# STM32U5A9 register map
File version: 0.2
CPU: CM33 r0p1, little endian, MPU, FPU, 4 interrupt priority bits
Registers are 32-bit, read-write, reset 0x0 unless marked. A register's access mark holds for its fields unless they carry their own. Offsets are from the block's base; [hi:lo] are bit positions; {n}, {i} and the like mark numbered series; 'fields as' and 'values as' point back to an identical list.

## PSSI
Base 0x4202C400
Same registers: SEC_PSSI 0x5202C400
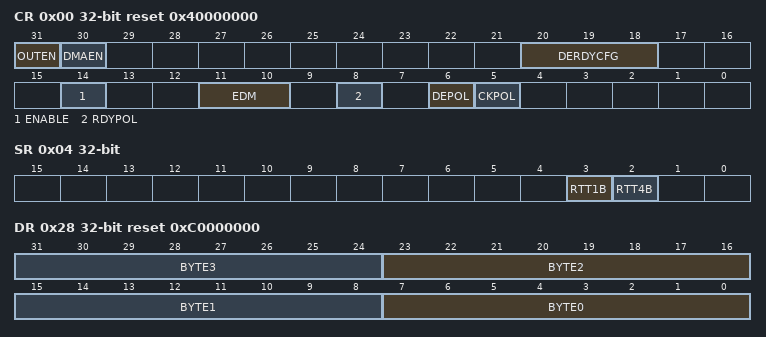
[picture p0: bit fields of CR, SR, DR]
0x00 CR reset 0x40000000 — PSSI control register
  [31] OUTEN — Data direction selection bit
  [30] DMAEN — DMA enable bit
  [20:18] DERDYCFG — Data enable and ready configuration When the PSSI_RDY function is mapped to the PSSI_DE pin (settings 101 or 111), it is still the RDYPOL bit which determines its polarity. Similarly, when the PSSI_DE function is mapped to the PSSI_RDY pin (settings 110 or 111), it is still the DEPOL bit which determines its polarity.
  [14] ENABLE — PSSI enable The contents of the FIFO are flushed when ENABLE is cleared to 0. Note: When ENABLE=1, the content of PSSI_CR must not be changed, except for the ENABLE bit itself. All configuration bits can change as soon as ENABLE changes from 0 to 1. The DMA controller and all PSSI configuration registers must be programmed correctly before setting the ENABLE bit to 1. The ENABLE bit and the DCMI ENABLE bit (bit 15 of DCMI_CR) must not be set to 1 at the same time.
  [11:10] EDM — Extended data mode
  [8] RDYPOL — Ready (PSSI_RDY) polarity This bit indicates the level on the PSSI_RDY pin when the data are not valid on the parallel interface.
  [6] DEPOL — Data enable (PSSI_DE) polarity This bit indicates the level on the PSSI_DE pin when the data are not valid on the parallel interface.
  [5] CKPOL — Parallel data clock polarity This bit configures the capture edge of the parallel clock or the edge used for driving outputs, depending on OUTEN.
0x04 SR ro — PSSI status register
  [3] RTT1B, [2] RTT4B
0x08 RIS ro — PSSI raw interrupt status register
  [1] OVR_RIS
0x0C IER — PSSI interrupt enable register
  [1] OVR_IE
0x10 MIS ro — PSSI masked interrupt status register
  [1] OVR_MIS
0x14 ICR wo — PSSI interrupt clear register
  [1] OVR_ISC
0x28 DR reset 0xC0000000 — PSSI data register
  [8n+7:8n] BYTE{n} (n=0..3) — Data byte {n}

## RAMCFG
Base 0x40026000
Same registers: SEC_RAMCFG 0x50026000
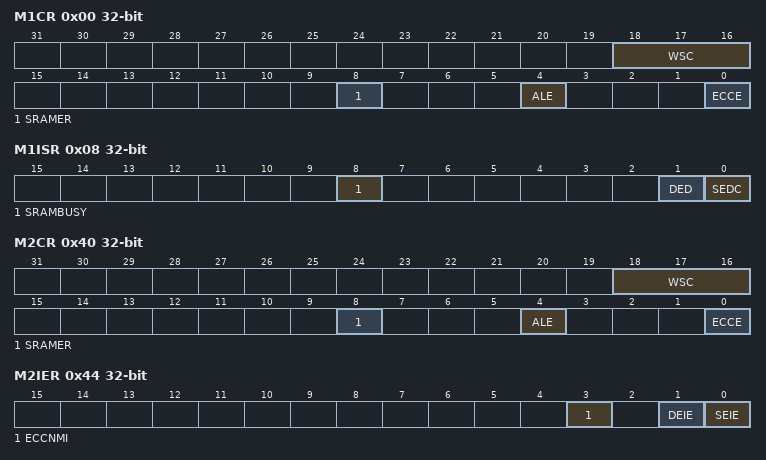
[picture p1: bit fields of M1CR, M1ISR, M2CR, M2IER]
0x00 M1CR — RAMCFG SRAM x control register
  [18:16] WSC, [8] SRAMER, [4] ALE, [0] ECCE
0x08 M1ISR ro — RAMCFG RAMx interrupt status register
  [8] SRAMBUSY, [1] DED, [0] SEDC
0x28 RAM1ERKEYR wo — RAMCFG SRAM x erase key register
  [7:0] ERASEKEY
0x40 M2CR — RAMCFG SRAM x control register
  [18:16] WSC, [8] SRAMER, [4] ALE, [0] ECCE
0x44 M2IER — RAMCFG SRAM x interrupt enable register
  [3] ECCNMI, [1] DEIE, [0] SEIE
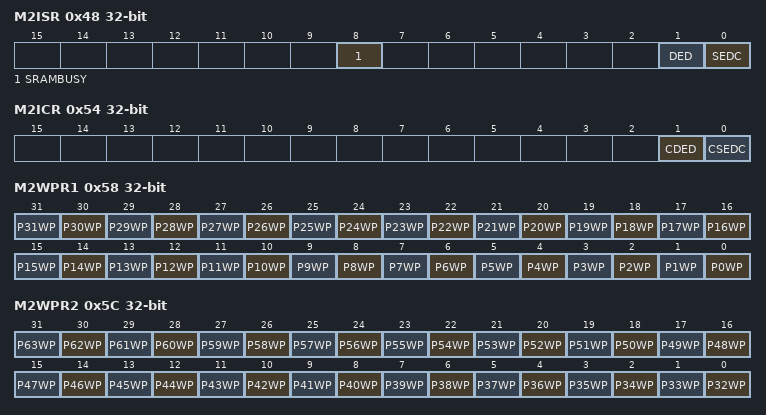
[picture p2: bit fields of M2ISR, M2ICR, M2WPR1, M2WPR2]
0x48 M2ISR ro — RAMCFG RAMx interrupt status register
  [8] SRAMBUSY, [1] DED, [0] SEDC
0x4C M2SEAR ro — RAMCFG RAM x ECC single error address register
  [31:0] ESEA
0x50 M2DEAR ro — RAMCFG RAM x ECC double error address register
  [31:0] EDEA
0x54 M2ICR — RAMCFG RAM x interrupt clear register x
  [1] CDED, [0] CSEDC
0x58 M2WPR1 — RAMCFG SRAM2 write protection register 1
  [n] P{n}WP (n=0..31)
0x5C M2WPR2 — RAMCFG SRAM2 write protection register 2
  [n-32] P{n}WP (n=32..63)
0x64 M2ECCKEYR wo — RAMCFG SRAM x ECC key register
  [7:0] ECCKEY
0x68 M2ERKEYR wo — RAMCFG SRAM x erase key register
  [7:0] ERASEKEY
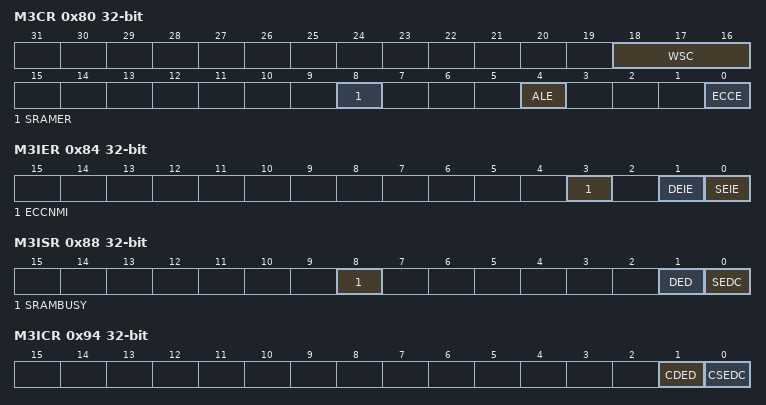
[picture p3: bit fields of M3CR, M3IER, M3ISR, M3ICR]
0x80 M3CR — RAMCFG SRAM x control register
  [18:16] WSC, [8] SRAMER, [4] ALE, [0] ECCE
0x84 M3IER — RAMCFG SRAM x interrupt enable register
  [3] ECCNMI, [1] DEIE, [0] SEIE
0x88 M3ISR ro — RAMCFG RAMx interrupt status register
  [8] SRAMBUSY, [1] DED, [0] SEDC
0x8C M3SEAR ro — RAMCFG RAM x ECC single error address register
  [31:0] ESEA
0x90 M3DEAR ro — RAMCFG RAM x ECC double error address register
  [31:0] EDEA
0x94 M3ICR — RAMCFG RAM x interrupt clear register x
  [1] CDED, [0] CSEDC
0xA4 M3ECCKEYR wo — RAMCFG SRAM x ECC key register
  [7:0] ECCKEY
0xA8 M3ERKEYR wo — RAMCFG SRAM x erase key register
  [7:0] ERASEKEY
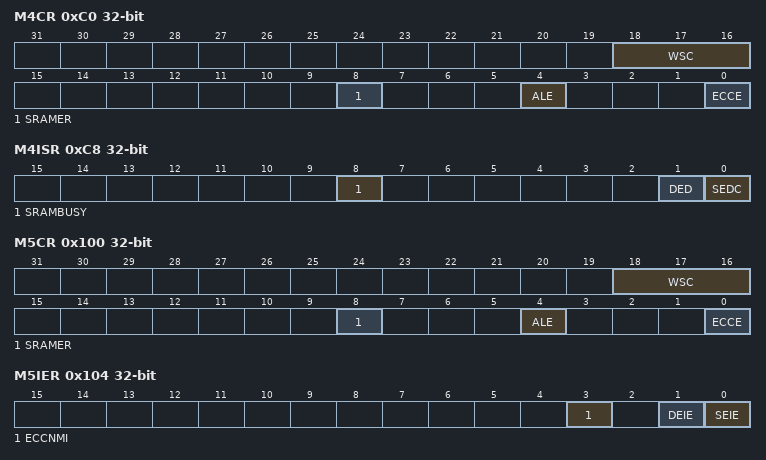
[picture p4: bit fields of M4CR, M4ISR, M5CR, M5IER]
0xC0 M4CR — RAMCFG SRAM x control register
  [18:16] WSC, [8] SRAMER, [4] ALE, [0] ECCE
0xC8 M4ISR ro — RAMCFG RAMx interrupt status register
  [8] SRAMBUSY, [1] DED, [0] SEDC
0xE8 M4ERKEYR wo — RAMCFG SRAM x erase key register
  [7:0] ERASEKEY
0x100 M5CR — RAMCFG SRAM x control register
  [18:16] WSC, [8] SRAMER, [4] ALE, [0] ECCE
0x104 M5IER — RAMCFG SRAM x interrupt enable register
  [3] ECCNMI, [1] DEIE, [0] SEIE
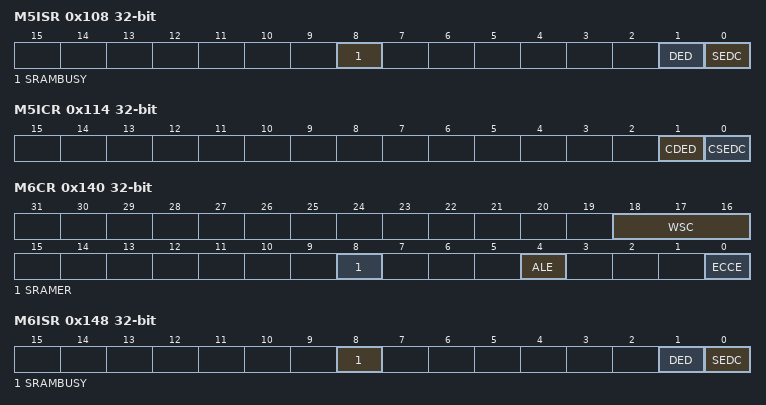
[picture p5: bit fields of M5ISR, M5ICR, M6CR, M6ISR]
0x108 M5ISR ro — RAMCFG RAMx interrupt status register
  [8] SRAMBUSY, [1] DED, [0] SEDC
0x10C M5SEAR ro — RAMCFG RAM x ECC single error address register
  [31:0] ESEA
0x110 M5DEAR ro — RAMCFG RAM x ECC double error address register
  [31:0] EDEA
0x114 M5ICR — RAMCFG RAM x interrupt clear register x
  [1] CDED, [0] CSEDC
0x124 M5ECCKEYR — RAMCFG RAM x interrupt clear register x
  [7:0] ECCKEY
0x128 M5ERKEYR
  [7:0] ERASEKEY wo — Erase write protection key The following steps are required to unlock the write protection of the SRAMER bit in the RAMCFG_MxCR register. 1) Write 0xCA into ERASEKEY[7:0]. 2) Write 0x53 into ERASEKEY[7:0]. Note: Writing a wrong key reactivates the write protection.
0x140 M6CR — memory x control register
  [18:16] WSC, [8] SRAMER, [4] ALE, [0] ECCE
0x148 M6ISR ro
  [8] SRAMBUSY — SRAM busy with erase operation Note: Depending on the SRAM, the erase operation can be performed due to software request, system reset if the option bit is enabled, tamper detection or readout protection regression. Refer to .
  [1] DED — ECC double error detected Note: This bit is reserved and must be kept at reset value in SRAM1, SRAM4 and SRAM5 interrupt status registers.
  [0] SEDC — ECC single error detected and corrected Note: This bit is reserved and must be kept at reset value in SRAM1, SRAM4 and SRAM5 interrupt status registers.
0x168 M6ERKEYR
  fields as M5ERKEYR
